# HC32M458 register map
File version: 1.0
CPU: CM4 r0p1, little endian, MPU, FPU, 4 interrupt priority bits
Registers are 16-bit, read-write, reset 0x0 unless marked. A register's access mark holds for its fields unless they carry their own. Offsets are from the block's base; [hi:lo] are bit positions; {n}, {i} and the like mark numbered series; 'fields as' and 'values as' point back to an identical list.

## PWC
Base 0x40054400
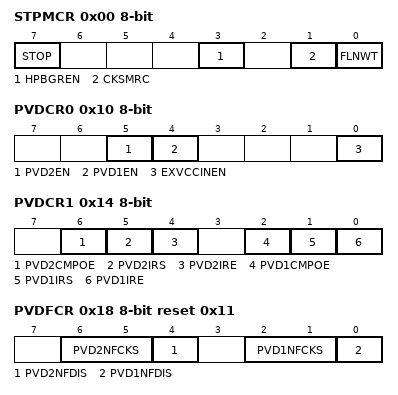
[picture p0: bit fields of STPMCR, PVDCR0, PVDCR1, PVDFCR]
0x00 STPMCR 8-bit
  [7] STOP, [3] HPBGREN, [1] CKSMRC, [0] FLNWT
0x10 PVDCR0 8-bit
  [5] PVD2EN, [4] PVD1EN, [0] EXVCCINEN
0x14 PVDCR1 8-bit
  [6] PVD2CMPOE, [5] PVD2IRS, [4] PVD2IRE, [2] PVD1CMPOE, [1] PVD1IRS, [0] PVD1IRE
0x18 PVDFCR 8-bit reset 0x11
  [6:5] PVD2NFCKS, [4] PVD2NFDIS, [2:1] PVD1NFCKS, [0] PVD1NFDIS
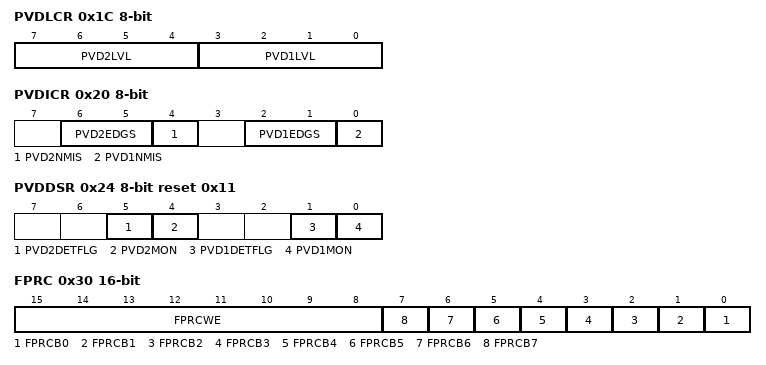
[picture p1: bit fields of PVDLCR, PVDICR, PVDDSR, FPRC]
0x1C PVDLCR 8-bit
  [7:4] PVD2LVL, [3:0] PVD1LVL
0x20 PVDICR 8-bit
  [6:5] PVD2EDGS, [4] PVD2NMIS, [2:1] PVD1EDGS, [0] PVD1NMIS
0x24 PVDDSR 8-bit reset 0x11
  [5] PVD2DETFLG, [4] PVD2MON ro, [1] PVD1DETFLG, [0] PVD1MON ro
0x30 FPRC
  [15:8] FPRCWE wo, [n] FPRCB{n} (n=0..7)
0x40 DBGC
  [0] DBGEN
0x50 LPMCSR ro
  [0] LPMF
0x52 LPMCSCR
  [0] LPMFC

## RMU
Base 0x40054500
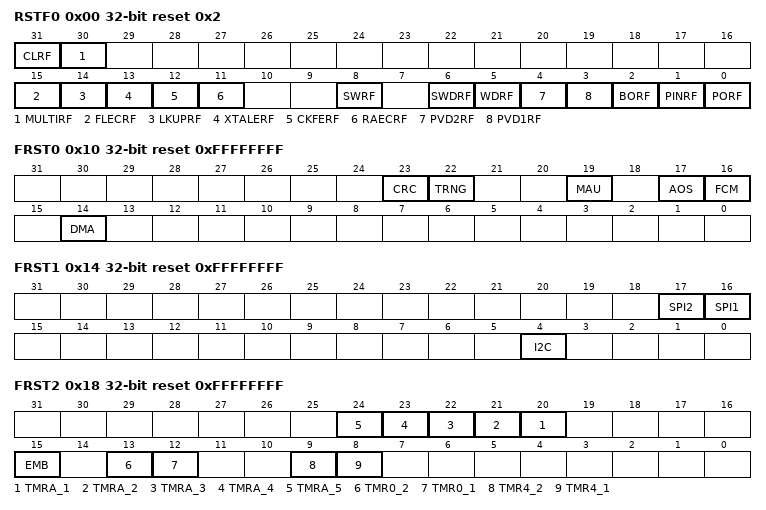
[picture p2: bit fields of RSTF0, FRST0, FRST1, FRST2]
0x00 RSTF0 32-bit reset 0x2
  [31] CLRF wo, [30] MULTIRF ro, [15] FLECRF ro, [14] LKUPRF ro, [13] XTALERF ro, [12] CKFERF ro, [11] RAECRF ro, [8] SWRF ro, [6] SWDRF ro, [5] WDRF ro, [4] PVD2RF ro, [3] PVD1RF ro, [2] BORF ro, [1] PINRF ro, [0] PORF ro
0x10 FRST0 32-bit reset 0xFFFFFFFF
  [23] CRC, [22] TRNG, [19] MAU, [17] AOS, [16] FCM, [14] DMA
0x14 FRST1 32-bit reset 0xFFFFFFFF
  [17] SPI2, [16] SPI1, [4] I2C
0x18 FRST2 32-bit reset 0xFFFFFFFF
  [n+19] TMRA_{n} (n=1..5), [15] EMB, [13] TMR0_2, [12] TMR0_1, [9] TMR4_2, [8] TMR4_1
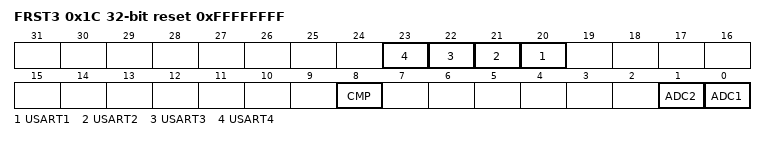
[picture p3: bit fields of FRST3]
0x1C FRST3 32-bit reset 0xFFFFFFFF
  [n+19] USART{n} (n=1..4), [8] CMP, [1] ADC2, [0] ADC1

## SPI1 — desc SPI
Base 0x4001C000
Same registers: SPI2 0x4001C400
0x00 DR 32-bit
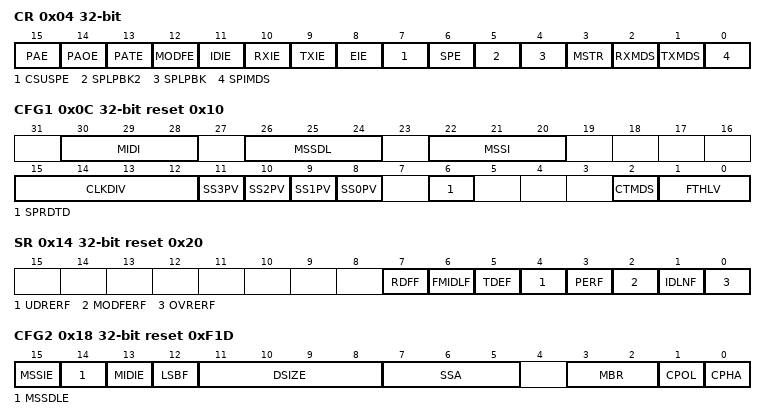
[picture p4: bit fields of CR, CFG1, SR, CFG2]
0x04 CR 32-bit
  [15] PAE, [14] PAOE, [13] PATE, [12] MODFE, [11] IDIE, [10] RXIE, [9] TXIE, [8] EIE, [7] CSUSPE, [6] SPE, [5] SPLPBK2, [4] SPLPBK, [3] MSTR, [2] RXMDS, [1] TXMDS, [0] SPIMDS
0x0C CFG1 32-bit reset 0x10
  [30:28] MIDI, [26:24] MSSDL, [22:20] MSSI, [15:12] CLKDIV, [n+8] SS{n}PV (n=0..3), [6] SPRDTD, [2] CTMDS, [1:0] FTHLV
0x14 SR 32-bit reset 0x20
  [7] RDFF ro, [6] FMIDLF ro, [5] TDEF ro, [4] UDRERF, [3] PERF, [2] MODFERF, [1] IDLNF ro, [0] OVRERF
0x18 CFG2 32-bit reset 0xF1D
  [15] MSSIE, [14] MSSDLE, [13] MIDIE, [12] LSBF, [11:8] DSIZE, [7:5] SSA, [3:2] MBR, [1] CPOL, [0] CPHA

## SRAMC
Base 0x40050800
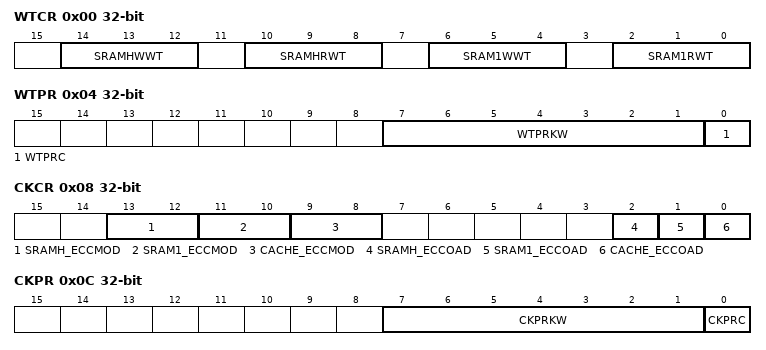
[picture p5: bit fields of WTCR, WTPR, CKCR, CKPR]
0x00 WTCR 32-bit
  [14:12] SRAMHWWT, [10:8] SRAMHRWT, [6:4] SRAM1WWT, [2:0] SRAM1RWT
0x04 WTPR 32-bit
  [7:1] WTPRKW, [0] WTPRC
0x08 CKCR 32-bit
  [13:12] SRAMH_ECCMOD, [11:10] SRAM1_ECCMOD, [9:8] CACHE_ECCMOD, [2] SRAMH_ECCOAD, [1] SRAM1_ECCOAD, [0] CACHE_ECCOAD
0x0C CKPR 32-bit
  [7:1] CKPRKW, [0] CKPRC
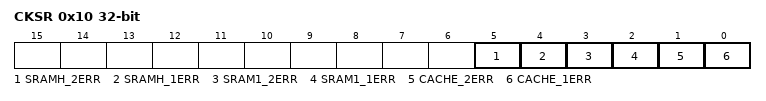
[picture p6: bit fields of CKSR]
0x10 CKSR 32-bit
  [5] SRAMH_2ERR, [4] SRAMH_1ERR, [3] SRAM1_2ERR, [2] SRAM1_1ERR, [1] CACHE_2ERR, [0] CACHE_1ERR
0x14 SRAM1_EIEN 32-bit
  [0] EIEN
0x18 SRAM1_EIBIT0 32-bit
0x1C SRAM1_EIBIT1 32-bit
  [6:0] EIBIT
0x20 SRAM1_ECCERRADDR 32-bit
  [16:0] ECCERRADDR
0x24 SRAMH_EIEN 32-bit
  [0] EIEN
0x28 SRAMH_EIBIT0 32-bit
0x2C SRAMH_EIBIT1 32-bit
  [6:0] EIBIT
0x30 SRAMH_ECCERRADDR 32-bit
  [16:0] ECCERRADDR

## SWDT
Base 0x40049400
Same registers: WDT 0x40049000
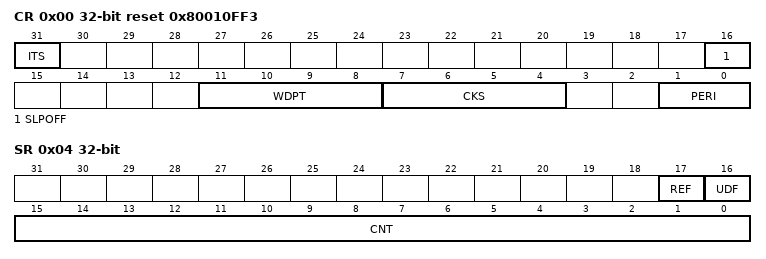
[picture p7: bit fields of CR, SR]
0x00 CR 32-bit reset 0x80010FF3
  [31] ITS, [16] SLPOFF, [11:8] WDPT, [7:4] CKS, [1:0] PERI
0x04 SR 32-bit
  [17] REF, [16] UDF, [15:0] CNT ro
0x08 RR 32-bit
  [15:0] RF

## TMR01 — desc TMR0
Base 0x40024000
Same registers: TMR02 0x40024400
0x00 CNTAR 32-bit
  [15:0] CNTA
0x04 CNTBR 32-bit
  [15:0] CNTB
0x08 CMPAR 32-bit reset 0xFFFF
  [15:0] CMPA
0x0C CMPBR 32-bit reset 0xFFFF
  [15:0] CMPB
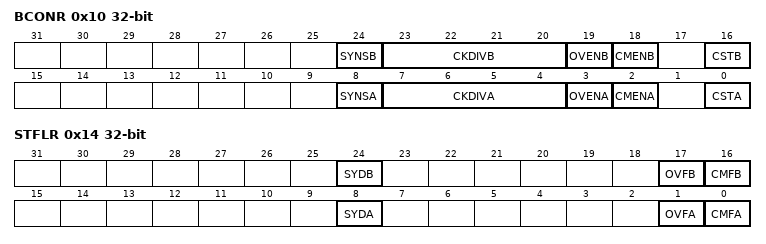
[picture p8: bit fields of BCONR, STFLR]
0x10 BCONR 32-bit
  [24] SYNSB, [23:20] CKDIVB, [19] OVENB, [18] CMENB, [16] CSTB, [8] SYNSA, [7:4] CKDIVA, [3] OVENA, [2] CMENA, [0] CSTA
0x14 STFLR 32-bit
  [24] SYDB ro, [17] OVFB, [16] CMFB, [8] SYDA ro, [1] OVFA, [0] CMFA

## TMR41
Base 0x40038000
0x00 OCCR1UH
0x02 OCCR2UH
0x04 OCCR1UL
0x06 OCCR2UL
0x08 OCCR1VH
0x0A OCCR2VH
0x0C OCCR1VL
0x0E OCCR2VL
0x10 OCCR1WH
0x12 OCCR2WH
0x14 OCCR1WL
0x16 OCCR2WL
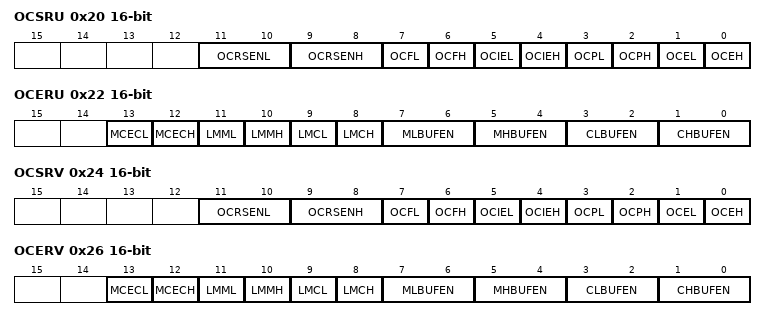
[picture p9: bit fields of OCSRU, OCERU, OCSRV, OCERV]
0x20 OCSRU
  [11:10] OCRSENL, [9:8] OCRSENH, [7] OCFL, [6] OCFH, [5] OCIEL, [4] OCIEH, [3] OCPL, [2] OCPH, [1] OCEL, [0] OCEH
0x22 OCERU
  [13] MCECL, [12] MCECH, [11] LMML, [10] LMMH, [9] LMCL, [8] LMCH, [7:6] MLBUFEN, [5:4] MHBUFEN, [3:2] CLBUFEN, [1:0] CHBUFEN
0x24 OCSRV
  fields as OCSRU
0x26 OCERV
  fields as OCERU
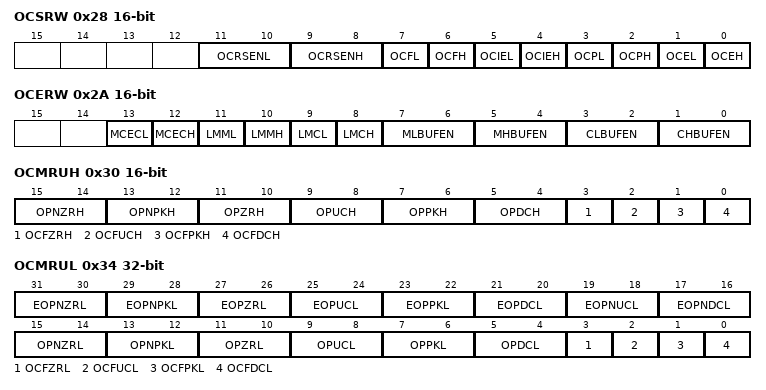
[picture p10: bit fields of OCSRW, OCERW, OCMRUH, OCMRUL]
0x28 OCSRW
  fields as OCSRU
0x2A OCERW
  fields as OCERU
0x30 OCMRUH
  [15:14] OPNZRH, [13:12] OPNPKH, [11:10] OPZRH, [9:8] OPUCH, [7:6] OPPKH, [5:4] OPDCH, [3] OCFZRH, [2] OCFUCH, [1] OCFPKH, [0] OCFDCH
0x34 OCMRUL 32-bit
  [31:30] EOPNZRL, [29:28] EOPNPKL, [27:26] EOPZRL, [25:24] EOPUCL, [23:22] EOPPKL, [21:20] EOPDCL, [19:18] EOPNUCL, [17:16] EOPNDCL, [15:14] OPNZRL, [13:12] OPNPKL, [11:10] OPZRL, [9:8] OPUCL, [7:6] OPPKL, [5:4] OPDCL, [3] OCFZRL, [2] OCFUCL, [1] OCFPKL, [0] OCFDCL
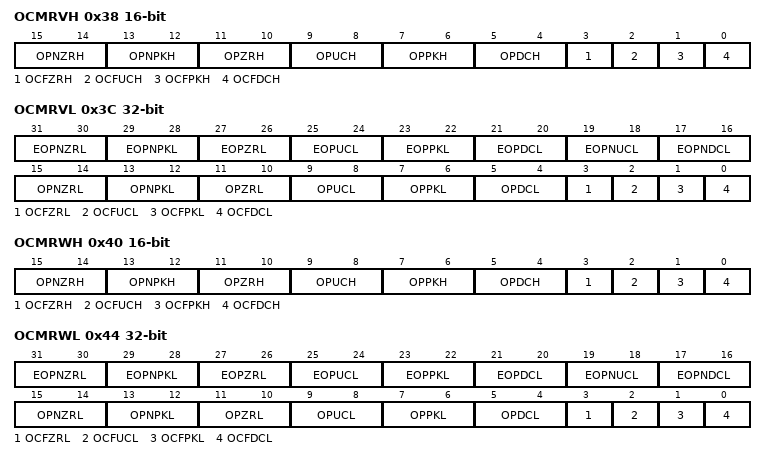
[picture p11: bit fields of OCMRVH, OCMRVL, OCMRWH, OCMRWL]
0x38 OCMRVH
  fields as OCMRUH
0x3C OCMRVL 32-bit
  fields as OCMRUL
0x40 OCMRWH
  fields as OCMRUH
0x44 OCMRWL 32-bit
  fields as OCMRUL
0x50 CPSR reset 0xFFFF
0x54 CNTR
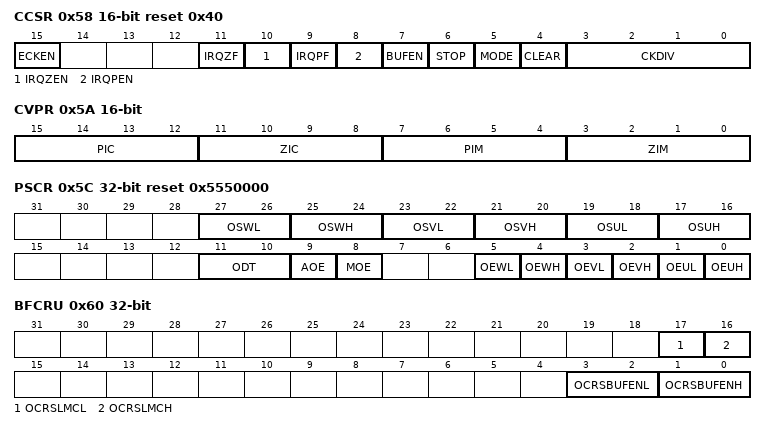
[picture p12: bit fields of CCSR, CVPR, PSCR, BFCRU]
0x58 CCSR reset 0x40
  [15] ECKEN, [11] IRQZF, [10] IRQZEN, [9] IRQPF, [8] IRQPEN, [7] BUFEN, [6] STOP, [5] MODE, [4] CLEAR, [3:0] CKDIV
0x5A CVPR
  [15:12] PIC ro, [11:8] ZIC ro, [7:4] PIM, [3:0] ZIM
0x5C PSCR 32-bit reset 0x5550000
  [27:26] OSWL, [25:24] OSWH, [23:22] OSVL, [21:20] OSVH, [19:18] OSUL, [17:16] OSUH, [11:10] ODT, [9] AOE, [8] MOE, [5] OEWL, [4] OEWH, [3] OEVL, [2] OEVH, [1] OEUL, [0] OEUH
0x60 BFCRU 32-bit
  [17] OCRSLMCL, [16] OCRSLMCH, [3:2] OCRSBUFENL, [1:0] OCRSBUFENH
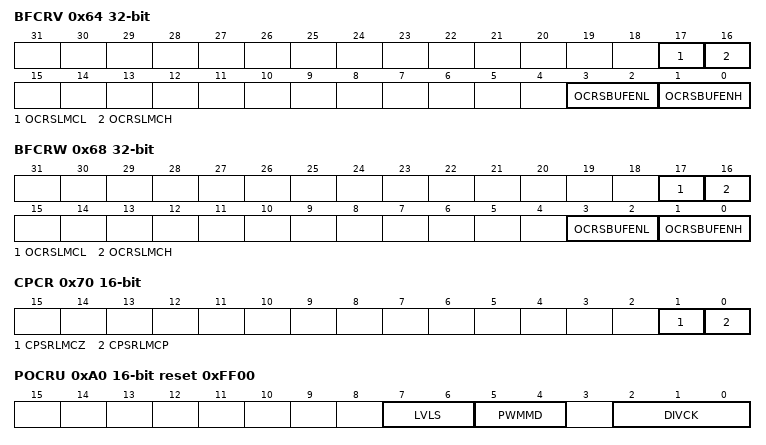
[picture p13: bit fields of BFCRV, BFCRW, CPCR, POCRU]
0x64 BFCRV 32-bit
  [17] OCRSLMCL, [16] OCRSLMCH, [3:2] OCRSBUFENL, [1:0] OCRSBUFENH
0x68 BFCRW 32-bit
  [17] OCRSLMCL, [16] OCRSLMCH, [3:2] OCRSBUFENL, [1:0] OCRSBUFENH
0x70 CPCR
  [1] CPSRLMCZ, [0] CPSRLMCP
0x82 PFSRU
0x84 PDARU
0x86 PDBRU
0x8A PFSRV
0x8C PDARV
0x8E PDBRV
0x92 PFSRW
0x94 PDARW
0x96 PDBRW
0xA0 POCRU reset 0xFF00
  [7:6] LVLS, [5:4] PWMMD, [2:0] DIVCK
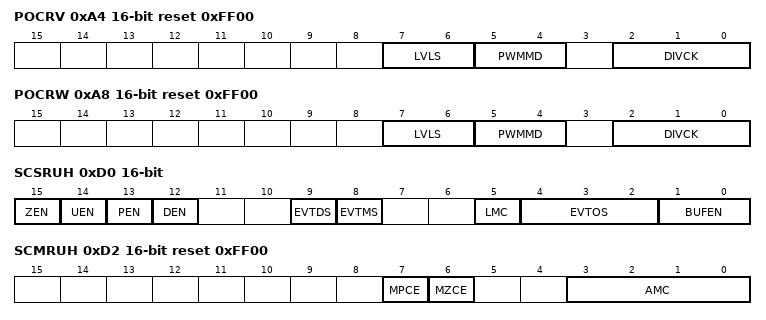
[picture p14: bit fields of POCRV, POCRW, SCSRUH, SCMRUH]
0xA4 POCRV reset 0xFF00
  [7:6] LVLS, [5:4] PWMMD, [2:0] DIVCK
0xA8 POCRW reset 0xFF00
  [7:6] LVLS, [5:4] PWMMD, [2:0] DIVCK
0xB0 SCCRUH
0xB4 SCCRUL
0xB8 SCCRVH
0xBC SCCRVL
0xC0 SCCRWH
0xC4 SCCRWL
0xD0 SCSRUH
  [15] ZEN, [14] UEN, [13] PEN, [12] DEN, [9] EVTDS, [8] EVTMS, [5] LMC, [4:2] EVTOS, [1:0] BUFEN
0xD2 SCMRUH reset 0xFF00
  [7] MPCE, [6] MZCE, [3:0] AMC
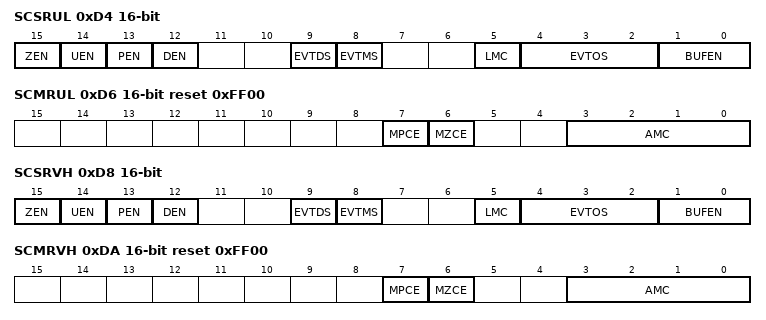
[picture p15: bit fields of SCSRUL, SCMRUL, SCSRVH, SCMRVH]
0xD4 SCSRUL
  fields as SCSRUH
0xD6 SCMRUL reset 0xFF00
  [7] MPCE, [6] MZCE, [3:0] AMC
0xD8 SCSRVH
  fields as SCSRUH
0xDA SCMRVH reset 0xFF00
  [7] MPCE, [6] MZCE, [3:0] AMC
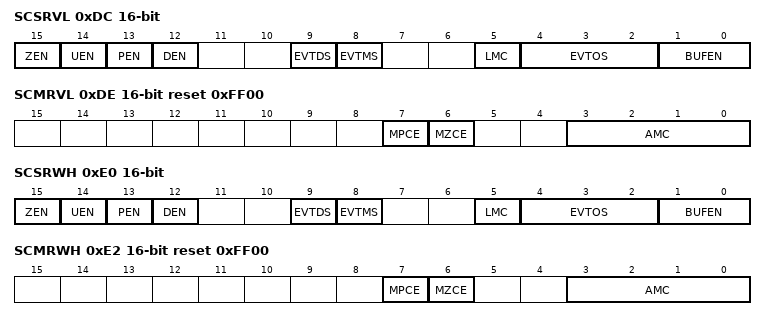
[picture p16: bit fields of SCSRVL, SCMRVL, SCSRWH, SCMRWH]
0xDC SCSRVL
  fields as SCSRUH
0xDE SCMRVL reset 0xFF00
  [7] MPCE, [6] MZCE, [3:0] AMC
0xE0 SCSRWH
  fields as SCSRUH
0xE2 SCMRWH reset 0xFF00
  [7] MPCE, [6] MZCE, [3:0] AMC
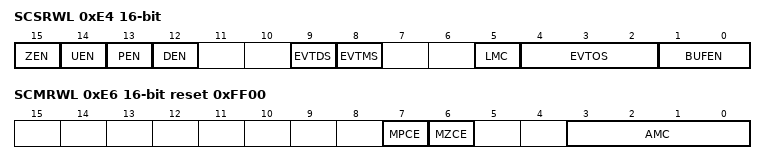
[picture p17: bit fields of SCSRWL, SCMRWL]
0xE4 SCSRWL
  fields as SCSRUH
0xE6 SCMRWL reset 0xFF00
  [7] MPCE, [6] MZCE, [3:0] AMC
0xF0 SCER
  [8] PCTS, [3:0] EVTRS
0xF4 RCSR 32-bit reset 0xFFFF0000
  [15] RTSW, [14] RTEW, [13] RTICW, [12] RTIFW ro, [11] RTSV, [10] RTEV, [9] RTICV, [8] RTIFV ro, [7] RTSU, [6] RTEU, [5] RTICU, [4] RTIFU ro, [2] RTIDW, [1] RTIDV, [0] RTIDU
0xF8 SCIR reset 0xFFC0
  [n] ITEN{n} (n=0..5)
0xFC SCFR reset 0xFFC0
  [n] SF{n} (n=0..5)
0x100 OCCR3UH
0x104 OCCR3UL
0x108 OCCR3VH
0x10C OCCR3VL
0x110 OCCR3WH
0x114 OCCR3WL

## TMR42
Base 0x40038400
Registers as TMR41; these are added or differ:
0x58 CCSR reset 0x40
  [15] ECKEN, [12] SYNST, [11] IRQZF, [10] IRQZEN, [9] IRQPF, [8] IRQPEN, [7] BUFEN, [6] STOP, [5] MODE, [4] CLEAR, [3:0] CKDIV

## TMRA1 — desc TMRA
Base 0x4003A000
Same registers: TMRA5 0x40026000, TMRA2 0x4003A400, TMRA3 0x4003A800, TMRA4 0x4003AC00
0x00 CNTER 32-bit
  [31:0] CNT
0x04 PERAR 32-bit reset 0xFFFFFFFF
  [31:0] PER
{0x3C+4i} CMPAR{i} 32-bit reset 0xFFFFFFFF (i=1..6)
  [31:0] CMP
0x80 BCSTRL 8-bit reset 0x2
  [7:4] CKDIV, [3] SYNST, [2] MODE, [1] DIR, [0] START
0x81 BCSTRH 8-bit
  [7] UDFF, [6] OVFF, [5] ITENUDF, [4] ITENOVF, [0] OVSTP
0x84 HCONR
  [n+9] HCLE{n} (n=3..6), [9] HCLE1, [8] HCLE0, [5] HSTP1, [4] HSTP0, [1] HSTA1, [0] HSTA0
0x88 HCUPR
  [n] HCUP{n} (n=0..12)
0x8C HCDOR
  [n] HCDO{n} (n=0..12)
0x90 ICONR
  [n-1] ITEN{n} (n=1..6)
0x94 ECONR
  [n-1] ETEN{n} (n=1..6)
0x98 FCONR
  [14:13] NOFICKCB, [12] NOFIENCB, [10:9] NOFICKCA, [8] NOFIENCA, [2:1] NOFICKTG, [0] NOFIENTG
0x9C STFLR
  [n+7] ICPF{n} (n=1..6), [n-1] CMPF{n} (n=1..6)
{0xB8+8i} BCONR{i} (i=1..3)
  [3] BSEN, [2] BSE1, [1] BSE0, [0] BEN
{0xFC+4i} CCONR{i} (i=1..6)
  [14:13] NOFICKCP, [12] NOFIENCP, [n+5] HICP{n} (n=3..6), [6] HICP2, [5] HICP1, [4] HICP0, [0] CAPMD
{0x13C+4i} PCONR{i} (i=1..6)
  [12] OUTEN, [9:8] FORC, [7:6] PERC, [5:4] CMPC, [3:2] STPC, [1:0] STAC
0x180 EPSCR
  [2n-1:2n-2] ESS{n} (n=1..6)
0x1A0 SPECONR
  [1] SPDIREN, [0] SPEN
0x1A4 PBCONR
  [2] PBSE1, [1] PBSE0, [0] PBEN
0x1A8 PHSCR
  [2:1] MSTSEL, [0] PHSMD

## TRNG
Base 0x40042000
0x00 CR 32-bit
  [3] ENDIE, [1] RUN, [0] EN
0x04 MR 32-bit reset 0x12
  [4:2] CNT, [0] LOAD
0x0C DR0 32-bit ro
0x10 DR1 32-bit ro

## USART1 — desc USART
Base 0x4001CC00
Same registers: USART2 0x4001D000, USART3 0x40020C00, USART4 0x40021000
0x00 SR 32-bit ro reset 0xC0
  [17] ABRF, [16] MPB, [15] ABRBUSY, [14] ABROVR, [13] ABRE, [12] LBM, [11] TEND, [10] LBD, [9] WKUP, [8] RTOF, [7] TXE, [6] TC, [5] RXNE, [4] BE, [3] ORE, [1] FE, [0] PE
0x04 TDR reset 0x1FF
  [9] MPID, [8:0] TDR
0x06 RDR ro
  [8:0] RDR
0x08 BRR 32-bit reset 0xFFFF
  [15:8] DIV_INTEGER, [6:0] DIV_FRACTION
0x0C CR1 32-bit reset 0x80000000
  [31] SBS, [30] NFE, [29] FBME, [28] ML, [26] CLBM, [25] CTEND, [24] MS, [23] CLBD, [22] CWKUP, [21] CBE, [20] CRTOF, [19] CORE, [17] CFE, [16] CPE, [15] OVER8, [13] ABREN, [12] M, [11] ABREI, [10] PCE, [9] PS, [8] TENDIE, [7] TXEIE, [6] TCIE, [5] RIE, [4] SLME, [3] TE, [2] RE, [1] RTOIE, [0] RTOE
0x10 CR2 32-bit reset 0x600
  [31:24] MPDR, [23] MKERR, [22] REIE, [19] LBMIE, [17] SBKM, [16] SBK, [15] UATSBKE, [14] LINEN, [13] STOP, [12:11] CLKC, [8] WKUPE, [7:6] SBKL, [5] LBDL, [4] LBDIE, [3] BEE, [2] BEIE, [1] WKUPIE, [0] MPE
0x14 CR3 32-bit
  [31] DEP, [30] DEM, [28:25] DEA, [19:18] ABRMOD, [17] CABR, [15:14] TDS, [13:10] DED, [9] CTSE, [8] RTSE, [4] LOOP, [3] HDSEL
0x18 PR 32-bit
  [11:8] RTOB, [4] ULBREN, [3:2] LBMPSC, [1:0] PSC
0x1C LBMC 32-bit ro
  [15:0] LBMC
